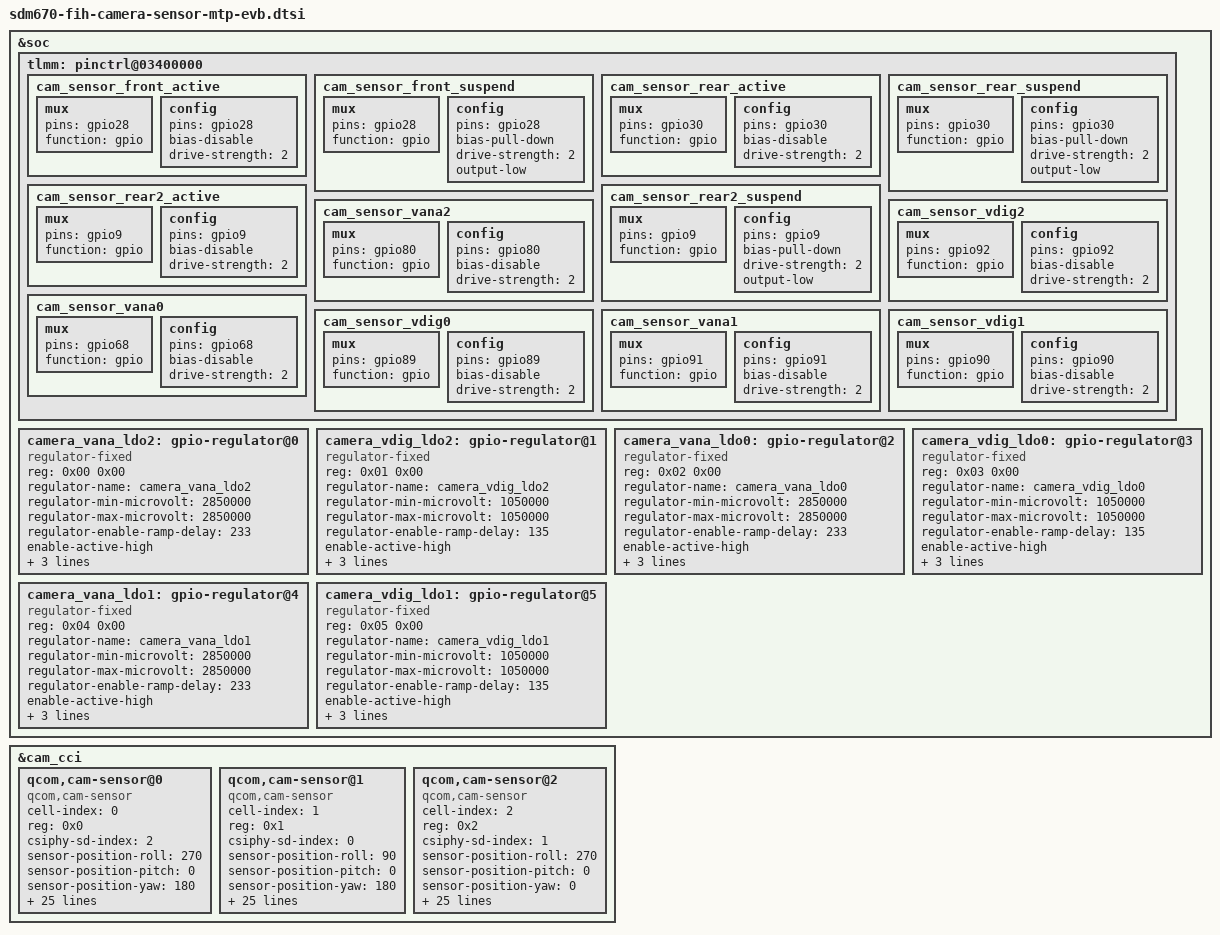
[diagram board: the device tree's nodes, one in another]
/*
 * Base on sdm670-camera-sensor-mtp.dtsi to overwrite setting
 */
 
&soc {
	tlmm: pinctrl@03400000 {
		/* Delete pinctrl node*/
		/delete-node/cam_sensor_front_active;
		/delete-node/cam_sensor_front_suspend;
		/delete-node/cam_sensor_rear_active;
		/delete-node/cam_sensor_rear_suspend;
		/delete-node/cam_sensor_rear2_active;
		/delete-node/cam_sensor_rear2_suspend;
	
		cam_sensor_front_active: cam_sensor_front_active {
			/* RESET  */
			mux {
				pins = "gpio28";
				function = "gpio";
			};

			config {
				pins = "gpio28";
				bias-disable; /* No PULL */
				drive-strength = <2>; /* 2 MA */
			};
		};

		cam_sensor_front_suspend: cam_sensor_front_suspend {
			/* RESET */
			mux {
				pins = "gpio28";
				function = "gpio";
			};

			config {
				pins = "gpio28";
				bias-pull-down; /* PULL DOWN */
				drive-strength = <2>; /* 2 MA */
				output-low;
			};
		};

		cam_sensor_rear_active: cam_sensor_rear_active {
			/* RESET */
			mux {
				pins = "gpio30";
				function = "gpio";
			};

			config {
				pins = "gpio30";
				bias-disable; /* No PULL */
				drive-strength = <2>; /* 2 MA */
			};
		};

		cam_sensor_rear_suspend: cam_sensor_rear_suspend {
			/* RESET */
			mux {
				pins = "gpio30";
				function = "gpio";
			};

			config {
				pins = "gpio30";
				bias-pull-down; /* PULL DOWN */
				drive-strength = <2>; /* 2 MA */
				output-low;
			};
		};

		cam_sensor_rear2_active: cam_sensor_rear2_active {
			/* RESET */
			mux {
				pins = "gpio9";
				function = "gpio";
			};

			config {
				pins = "gpio9";
				bias-disable; /* No PULL */
				drive-strength = <2>; /* 2 MA */
			};
		};

		cam_sensor_rear2_suspend: cam_sensor_rear2_suspend {
			/* RESET */
			mux {
				pins = "gpio9";
				function = "gpio";
			};

			config {
				pins = "gpio9";
				bias-pull-down; /* PULL DOWN */
				drive-strength = <2>; /* 2 MA */
				output-low;
			};
		};
		
		cam_sensor_vana2: cam_sensor_vana2 {
			/*  FRONT AVDD LDO */
			mux {
				pins = "gpio80";
				function = "gpio";
			};

			config {
				pins = "gpio80";
				bias-disable; /* No PULL */
				drive-strength = <2>; /* 2 MA */
			};
		};

		cam_sensor_vdig2: cam_sensor_vdig2 {
			/*  FRONT VDIG LDO */
			mux {
				pins = "gpio92";
				function = "gpio";
			};

			config {
				pins = "gpio92";
				bias-disable; /* No PULL */
				drive-strength = <2>; /* 2 MA */
			};
		};

		cam_sensor_vana0: cam_sensor_vana0 {
			/*  WIDE AVDD LDO */
			mux {
				pins = "gpio68";
				function = "gpio";
			};

			config {
				pins = "gpio68";
				bias-disable; /* No PULL */
				drive-strength = <2>; /* 2 MA */
			};
		};

		cam_sensor_vdig0: cam_sensor_vdig0 {
			/*  WIDE VDIG LDO */
			mux {
				pins = "gpio89";
				function = "gpio";
			};

			config {
				pins = "gpio89";
				bias-disable; /* No PULL */
				drive-strength = <2>; /* 2 MA */
			};
		};

		cam_sensor_vana1: cam_sensor_vana1 {
			/*  TELE AVDD LDO */
			mux {
				pins = "gpio91";
				function = "gpio";
			};

			config {
				pins = "gpio91";
				bias-disable; /* No PULL */
				drive-strength = <2>; /* 2 MA */
			};
		};

		cam_sensor_vdig1: cam_sensor_vdig1 {
			/*  TELE VDIG LDO */
			mux {
				pins = "gpio90";
				function = "gpio";
			};

			config {
				pins = "gpio90";
				bias-disable; /* No PULL */
				drive-strength = <2>; /* 2 MA */
			};
		};
	};
};

&soc {
	camera_vana_ldo2: gpio-regulator@0 {
		compatible = "regulator-fixed";
		reg = <0x00 0x00>;
		regulator-name = "camera_vana_ldo2";
		regulator-min-microvolt = <2850000>;
		regulator-max-microvolt = <2850000>;
		regulator-enable-ramp-delay = <233>;
		enable-active-high;
		gpio = <&tlmm 80 0>;
		pinctrl-names = "default";
		pinctrl-0 = <&cam_sensor_vana2>;
		vin-supply = <&pm660l_bob>;
	};

	camera_vdig_ldo2: gpio-regulator@1 {
		compatible = "regulator-fixed";
		reg = <0x01 0x00>;
		regulator-name = "camera_vdig_ldo2";
		regulator-min-microvolt = <1050000>;
		regulator-max-microvolt = <1050000>;
		regulator-enable-ramp-delay = <135>;
		enable-active-high;
		gpio = <&tlmm 92 0>;
		pinctrl-names = "default";
		pinctrl-0 = <&cam_sensor_vdig2>;
		vin-supply = <&pm660_s4>;
	};

	camera_vana_ldo0: gpio-regulator@2 {
		compatible = "regulator-fixed";
		reg = <0x02 0x00>;
		regulator-name = "camera_vana_ldo0";
		regulator-min-microvolt = <2850000>;
		regulator-max-microvolt = <2850000>;
		regulator-enable-ramp-delay = <233>;
		enable-active-high;
		gpio = <&tlmm 68 0>;
		pinctrl-names = "default";
		pinctrl-0 = <&cam_sensor_vana0>;
		vin-supply = <&pm660l_bob>;
	};

	camera_vdig_ldo0: gpio-regulator@3 {
		compatible = "regulator-fixed";
		reg = <0x03 0x00>;
		regulator-name = "camera_vdig_ldo0";
		regulator-min-microvolt = <1050000>;
		regulator-max-microvolt = <1050000>;
		regulator-enable-ramp-delay = <135>;
		enable-active-high;
		gpio = <&tlmm 89 0>;
		pinctrl-names = "default";
		pinctrl-0 = <&cam_sensor_vdig0>;
		vin-supply = <&pm660_s4>;
	};

	camera_vana_ldo1: gpio-regulator@4 {
		compatible = "regulator-fixed";
		reg = <0x04 0x00>;
		regulator-name = "camera_vana_ldo1";
		regulator-min-microvolt = <2850000>;
		regulator-max-microvolt = <2850000>;
		regulator-enable-ramp-delay = <233>;
		enable-active-high;
		gpio = <&tlmm 91 0>;
		pinctrl-names = "default";
		pinctrl-0 = <&cam_sensor_vana1>;
		vin-supply = <&pm660l_bob>;
	};

	camera_vdig_ldo1: gpio-regulator@5 {
		compatible = "regulator-fixed";
		reg = <0x05 0x00>;
		regulator-name = "camera_vdig_ldo1";
		regulator-min-microvolt = <1050000>;
		regulator-max-microvolt = <1050000>;
		regulator-enable-ramp-delay = <135>;
		enable-active-high;
		gpio = <&tlmm 90 0>;
		pinctrl-names = "default";
		pinctrl-0 = <&cam_sensor_vdig1>;
		vin-supply = <&pm660_s4>;
	};
};

/* Delete cam_cci node*/
&cam_cci{
        /delete-node/qcom,cam-sensor@0;
        /delete-node/qcom,cam-sensor@1;
        /delete-node/qcom,cam-sensor@2;
};

&cam_cci {
	qcom,cam-sensor@0 {
		cell-index = <0>;
		compatible = "qcom,cam-sensor";
		reg = <0x0>;
		csiphy-sd-index = <2>;
		sensor-position-roll = <270>;
		sensor-position-pitch = <0>;
		sensor-position-yaw = <180>;
		cam_vio-supply = <&pm660_l11>;
		cam_vana-supply = <&camera_vana_ldo0>;
		cam_vdig-supply = <&camera_vdig_ldo0>;
		cam_clk-supply = <&titan_top_gdsc>;
		regulator-names = "cam_vio", "cam_vana", "cam_vdig",
			"cam_clk";
		rgltr-cntrl-support;
		rgltr-min-voltage = <1800000 2850000 1050000 0>;
		rgltr-max-voltage = <1800000 2850000 1050000 0>;
		rgltr-load-current = <0 80000 105000 0>;
		gpio-no-mux = <0>;
		pinctrl-names = "cam_default", "cam_suspend";
		pinctrl-0 = <&cam_sensor_mclk0_active
				&cam_sensor_rear_active>;
		pinctrl-1 = <&cam_sensor_mclk0_suspend
				&cam_sensor_rear_suspend>;
		gpios = <&tlmm 13 0>,
			<&tlmm 30 0>;
		gpio-reset = <1>;
		gpio-req-tbl-num = <0 1>;
		gpio-req-tbl-flags = <1 0>;
		gpio-req-tbl-label = "CAMIF_MCLK0",
					"CAM_RESET0";
		sensor-mode = <0>;
		cci-master = <0>;
		status = "ok";
		clocks = <&clock_camcc CAM_CC_MCLK0_CLK>;
		clock-names = "cam_clk";
		clock-cntl-level = "turbo";
		clock-rates = <24000000>;
	};

	qcom,cam-sensor@1 {
		cell-index = <1>;
		compatible = "qcom,cam-sensor";
		reg = <0x1>;
		csiphy-sd-index = <0>;
		sensor-position-roll = <90>;
		sensor-position-pitch = <0>;
		sensor-position-yaw = <180>;
		cam_vio-supply = <&pm660_l11>;
		cam_vana-supply = <&camera_vana_ldo1>;
		cam_vdig-supply = <&camera_vdig_ldo1>;
		cam_clk-supply = <&titan_top_gdsc>;
		regulator-names = "cam_vdig", "cam_vio", "cam_vana",
			"cam_clk";
		rgltr-cntrl-support;
		rgltr-min-voltage = <1050000 1800000 2850000 0>;
		rgltr-max-voltage = <1050000 1800000 2850000 0>;
		rgltr-load-current = <105000 0 80000 0>;
		gpio-no-mux = <0>;
		pinctrl-names = "cam_default", "cam_suspend";
		pinctrl-0 = <&cam_sensor_mclk2_active
				&cam_sensor_rear2_active>;
		pinctrl-1 = <&cam_sensor_mclk2_suspend
				&cam_sensor_rear2_suspend>;
		gpios = <&tlmm 15 0>,
			<&tlmm 9 0>;		
		gpio-reset = <1>;
		gpio-req-tbl-num = <0 1>;
		gpio-req-tbl-flags = <1 0>;
		gpio-req-tbl-label = "CAMIF_MCLK2",
					"CAM_RESET2";
		sensor-mode = <0>;
		cci-master = <1>;
		status = "ok";
		clocks = <&clock_camcc CAM_CC_MCLK2_CLK>;
		clock-names = "cam_clk";
		clock-cntl-level = "turbo";
		clock-rates = <24000000>;
	};

	qcom,cam-sensor@2 {
		cell-index = <2>;
		compatible = "qcom,cam-sensor";
		reg = <0x2>;
		csiphy-sd-index = <1>;
		sensor-position-roll = <270>;
		sensor-position-pitch = <0>;
		sensor-position-yaw = <0>;
		cam_vio-supply = <&pm660_l11>;
		cam_vana-supply = <&camera_vana_ldo2>;
		cam_vdig-supply = <&camera_vdig_ldo2>;
		cam_clk-supply = <&titan_top_gdsc>;
		regulator-names = "cam_vdig", "cam_vio", "cam_vana",
			"cam_clk";
		rgltr-cntrl-support;
		rgltr-min-voltage = <1050000 1800000 2850000 0>;
		rgltr-max-voltage = <1050000 1800000 2850000 0>;
		rgltr-load-current = <105000 0 80000 0>;
		gpio-no-mux = <0>;
		pinctrl-names = "cam_default", "cam_suspend";
		pinctrl-0 = <&cam_sensor_mclk1_active
				&cam_sensor_front_active>;
		pinctrl-1 = <&cam_sensor_mclk1_suspend
				&cam_sensor_front_suspend>;
		gpios = <&tlmm 14 0>,
			<&tlmm 28 0>;
		gpio-reset = <1>;
		gpio-req-tbl-num = <0 1>;
		gpio-req-tbl-flags = <1 0>;
		gpio-req-tbl-label = "CAMIF_MCLK1",
					"CAM_RESET1";
		sensor-mode = <0>;
		cci-master = <1>;
		status = "ok";
		clocks = <&clock_camcc CAM_CC_MCLK1_CLK>;
		clock-names = "cam_clk";
		clock-cntl-level = "turbo";
		clock-rates = <24000000>;
	};
};
